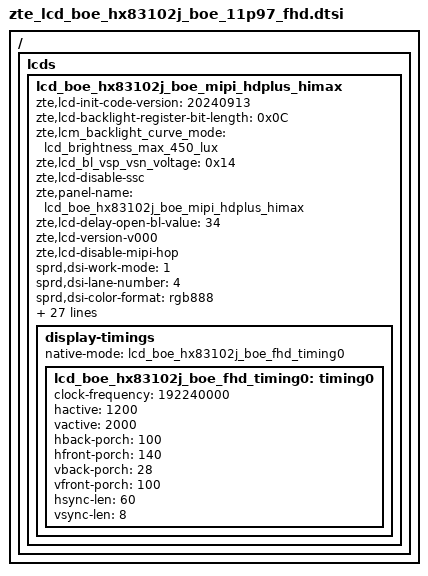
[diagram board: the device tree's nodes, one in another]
/ {
	fragment {
		target-path = "/";
		__overlay__ {
			lcds {
				lcd_boe_hx83102j_boe_mipi_hdplus_himax: lcd_boe_hx83102j_boe_mipi_hdplus_himax {
					zte,lcd-init-code-version = "20240913";

					zte,lcd-backlight-register-bit-length = <0x0C>;
					zte,lcm_backlight_curve_mode = "lcd_brightness_max_450_lux";
					zte,lcd_bl_vsp_vsn_voltage = <0x14>;
					zte,lcd-disable-ssc;
					zte,panel-name = "lcd_boe_hx83102j_boe_mipi_hdplus_himax";
					zte,lcd-delay-open-bl-value = <34>;
					zte,lcd-version-v000;
					zte,lcd-disable-mipi-hop;

					sprd,dsi-work-mode = <1>;
					sprd,dsi-lane-number = <4>;
					sprd,dsi-color-format = "rgb888";
					sprd,dpi-clk-div = <6>;
					sprd,video-lp-cmd-enable = <1>;
					sprd,hporch-lp-disable = <1>;
					sprd,slice-width = <600>;
					sprd,slice-height = <20>;
					sprd,output-bpc = <8>;
					sprd,dsc-enable = <0>;
					sprd,dual-dsi-enable = <0>;

					sprd,phy-bit-clock = <1153440>;
					sprd,phy-escape-clock = <20000>;/* kHz */

					sprd,width-mm = <15642>;
					sprd,height-mm = <26070>;

					sprd,esd-check-enable = <1>;/* 0:close , 1:open */
					sprd,esd-check-mode = <1>;/* 0:REG ,1:TE  */
					sprd,esd-check-period = <2000>;
					sprd,esd-check-register = <0x0A>;
					sprd,esd-check-value = <0x9C>;

					sprd,dphy-taget-val = <5>;

					sprd,reset-on-sequence = <1 5>, <0 2>, <1 50>;
					sprd,reset-off-sequence = <1 20>;

					sprd,use-gen-write;
					sprd,initial-command = [
						39 00 00 06 B9 83 10 21 55 00
						15 00 00 02 E9 C4
						15 00 00 02 D9 D2
						15 00 00 02 E9 3F
						39 00 00 1B B1 2C B1 B1 2D ED 42 E1 4D 36
										36 36 36 1A 8B 11 65 00 88 FA
										FF FF 8F FF 08 9A 33
						39 00 00 10 B2 00 47 B0 D0 00 22 62 3C 9B
										32 30 00 00 88 F5
						39 00 00 12 B4 88 88 6C 85 6C 85 89 6B 7C
										70 01 96 01 06 01 00 00
						15 00 00 02 E9 CD
						15 00 00 02 BA 84
						15 00 00 02 E9 3F
						39 00 00 03 BC 1B 04
						15 00 00 02 Be 20
						39 00 00 0B C0 3A 3A 22 11 22 A0 61 08 F5 03
						15 00 00 02 E9 CC
						15 00 00 02 C7 80
						15 00 00 02 E9 3F
						15 00 00 02 E9 C6
						15 00 00 02 C8 97
						15 00 00 02 E9 3F
						39 00 00 06 C9 00 1E 13 88 01
						39 00 00 07 CB 08 13 07 00 0E A1
						39 00 00 04 CC 02 03 44
						39 00 00 2D E1 11 00 00 89 30 80 07 D0 02
										58 00 14 02 58 02 58 02 00 02
										2C 00 20 02 02 00 08 00 0C 05
										0E 04 94 18 00 10 F0 03 0C 20
										00 06 0B 0B 33
						15 00 00 02 E9 C4
						15 00 00 02 D0 03
						15 00 00 02 E9 3F
						39 00 00 08 D1 37 06 00 02 04 0C FF
						39 00 00 23 D3 06 00 00 00 40 04 08 04 08
										37 47 64 4B 20 20 03 03 32 10
										1B 00 1B 32 10 16 00 16 32 17
										F7 07 F7 00 00
						39 00 00 2D D5 18 18 18 18 1F 1F 1F 1F 1E
										1E 1E 1E 24 24 24 24 01 00 01
										00 03 02 03 02 05 04 05 04 07
										06 07 06 21 20 21 20 18 18 18
										18 18 18 18 18
						39 00 00 0D D8 AF AA AA AA AA A0 AF AA AA AA AA A0
						39 00 00 18 E7 04 10 10 27 2C 96 02 BA 46
										14 14 00 00 00 00 12 05 02 02
										10 33 03 84
						15 00 00 02 BD 01
						39 00 00 04 B1 01 7F 11
						15 00 00 02 CB 86
						15 00 00 02 D2 B4
						15 00 00 02 E9 C9
						15 00 00 02 D3 84
						15 00 00 02 E9 3F
						39 00 00 02 E9 D1
						39 00 00 0A E1 F6 2B 34 2B 74 3B 74 6B F4
						39 00 00 02 E9 3F
						39 00 00 25 D8 FF FF FF FF FA A0 FF FF FF
										FF FA A0 FF FF FF FF FA A0 FF
										FF FF FF FA A0 FF FF FF FF FA
										A0 FF FF FF FF FA A0
						39 00 00 0C E7 02 00 3D 01 83 0F 80 10 A0 00 00
						15 00 00 02 BD 02
						39 00 00 0D D8 FF FF FF FF FA A0 FF FF FF FF FA A0
						39 00 00 1D E7 FE 03 FE 03 FE 03 02 02 02
										25 00 25 81 02 40 00 20 96 04
										03 02 01 00 00 00 00 01 00
						39 00 00 06 CB 02 00 00 0F D9
						15 00 00 02 BD 03
						39 00 00 25 D8 AA AF AA AA AA A0 AA AF AA
										AA AA A0 AA AF AA AA AA A0 AA
										AF AA AA AA A0 55 55 55 55 55
										50 55 55 55 55 55 50
						15 00 00 02 E1 00
						15 00 00 02 BD 00
						15 00 00 02 E9 C4
						15 00 00 02 BA 96
						15 00 00 02 E9 3F
						15 00 00 02 BD 01
						15 00 00 02 E9 C5
						15 00 00 02 BA 4F
						15 00 00 02 E9 3F
						15 00 00 02 BD 03
						15 00 00 02 E9 C6
						39 00 00 04 B4 03 FF F8
						15 00 00 02 E9 3F
						15 00 00 02 BD 00
						39 00 00 06 B9 00 00 00 00 00

						39 00 00 02 35 00
						05 64 00 01 11
						05 14 00 01 29
					];

					sprd,sleep-in-command = [
						15 01 00 02 AC 0A
						39 14 00 03 28 00 00
						39 78 00 03 10 00 00
						];
					sprd,sleep-out-command = [
						05 78 00 01 11
						05 14 00 01 29
						];
					display-timings {
						native-mode = <&lcd_boe_hx83102j_boe_fhd_timing0>;
						lcd_boe_hx83102j_boe_fhd_timing0: timing0 {
							clock-frequency = <192240000>;
							hactive = <1200>;
							vactive = <2000>;
							hback-porch = <100>;
							hfront-porch = <140>;
							vback-porch = <28>;
							vfront-porch = <100>;
							hsync-len = <60>;
							vsync-len = <8>;
						};
					};					
				};
			};
		};
	};
};
